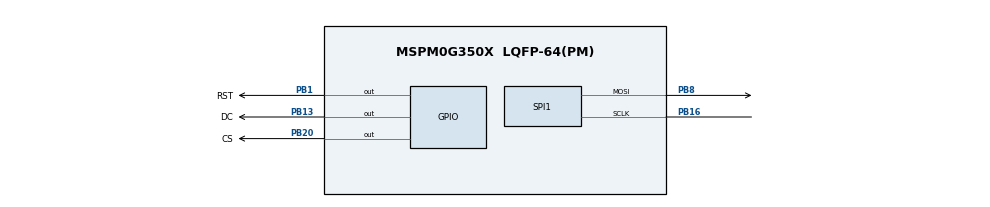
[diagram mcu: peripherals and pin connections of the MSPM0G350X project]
/**
 * @cliArgs --device "MSPM0G350X" --package "LQFP-64(PM)" --part "Default" --product "mspm0_sdk@2.01.00.03"
 * @versions {"tool":"1.20.0+3587"}
 */

/**
 * Import the modules used in this configuration.
 */
const GPIO   = scripting.addModule("/ti/driverlib/GPIO", {}, false);
const GPIO1  = GPIO.addInstance();
const SPI    = scripting.addModule("/ti/driverlib/SPI", {}, false);
const SPI1   = SPI.addInstance();
const SYSCTL = scripting.addModule("/ti/driverlib/SYSCTL");

/**
 * Write custom configuration values to the imported modules.
 */
GPIO1.$name                          = "GPIO_OUT";
GPIO1.port                           = "PORTB";
GPIO1.associatedPins.create(3);
GPIO1.associatedPins[0].$name        = "CS";
GPIO1.associatedPins[0].pin.$assign  = "PB20";
GPIO1.associatedPins[1].$name        = "RST";
GPIO1.associatedPins[1].initialValue = "SET";
GPIO1.associatedPins[1].pin.$assign  = "PB1";
GPIO1.associatedPins[2].$name        = "DC";
GPIO1.associatedPins[2].initialValue = "SET";
GPIO1.associatedPins[2].pin.$assign  = "PB13";

const Board = scripting.addModule("/ti/driverlib/Board", {}, false);

SPI1.$name                      = "SPI_0";
SPI1.spiClkDiv                  = "2";
SPI1.calculatedBitRate          = 1;
SPI1.peripheral.sclkPin.$assign = "PB16";
SPI1.peripheral.mosiPin.$assign = "PB8";
SPI1.sclkPinConfig.$name        = "ti_driverlib_gpio_GPIOPinGeneric0";
SPI1.mosiPinConfig.$name        = "ti_driverlib_gpio_GPIOPinGeneric1";
SPI1.misoPinConfig.$name        = "ti_driverlib_gpio_GPIOPinGeneric2";
SPI1.cs0PinConfig.$name         = "ti_driverlib_gpio_GPIOPinGeneric3";

SYSCTL.forceDefaultClkConfig = true;
SYSCTL.clockTreeEn           = true;

/**
 * Pinmux solution for unlocked pins/peripherals. This ensures that minor changes to the automatic solver in a future
 * version of the tool will not impact the pinmux you originally saw.  These lines can be completely deleted in order to
 * re-solve from scratch.
 */
Board.peripheral.$suggestSolution          = "DEBUGSS";
Board.peripheral.swclkPin.$suggestSolution = "PA20";
Board.peripheral.swdioPin.$suggestSolution = "PA19";
SPI1.peripheral.$suggestSolution           = "SPI1";
SPI1.peripheral.misoPin.$suggestSolution   = "PA16";
SPI1.peripheral.cs0Pin.$suggestSolution    = "PA2";
